# RN821X_RN721X_SOC_V2 register map
File version: v1.0.7
CPU: CM0 r0p0, little endian, no MPU, no FPU, 3 interrupt priority bits
Registers are 32-bit, read-write, reset 0x0 unless marked. A register's access mark holds for its fields unless they carry their own. Offsets are from the block's base; [hi:lo] are bit positions; {n}, {i} and the like mark numbered series.

## IOCNT — emu pulse forwarding module
Base 0x4006C000
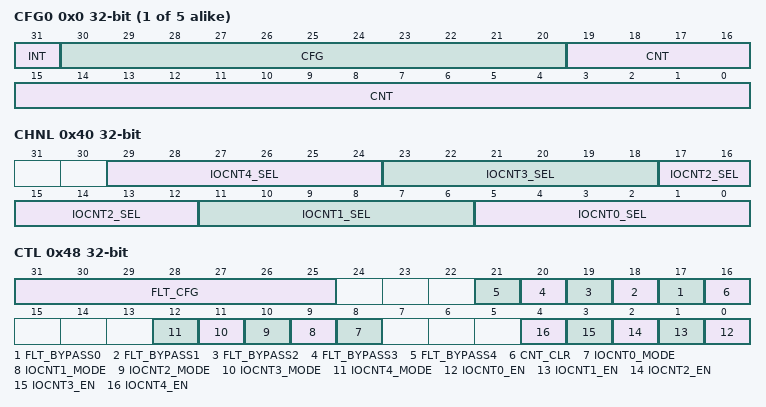
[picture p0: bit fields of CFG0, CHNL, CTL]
{0x0+4i} CFG{i} (i=0..4) — pulse forwarding configuration register{i+1}
  [31] INT — pluse inversion output enable bit
    0=NORM (output pulse level direction same as input pulse level); 1=INT (output pulse after it being inverted)
  [30:20] CFG — pluse freqency division configuration bits
  [19:0] CNT ro — pluse counter bits
{0x20+4i} OUT{i} (i=0..4) — pulse forwarding output counter register{i}
  [19:0] OUT{i} — pulse forwarding output counter bits
0x40 CHNL — pulse forwarding channel select register
  [6n+5:6n] IOCNT{n}_SEL (n=0..4) — IOCNT{n} input selection bits
0x48 CTL — pulse forwarding control register
  [31:25] FLT_CFG — IOCNT4~0 filter period config bits
  [n+17] FLT_BYPASS{n} (n=0..4) — IOCNT{n} FLT_BYPASS enable bit
  [16] CNT_CLR — pulse counter mode selection bit
  [n+8] IOCNT{n}_MODE (n=0..4) — IOCNT{n} count mode selection bit
  [n] IOCNT{n}_EN (n=0..4) — IOCNT{n} enable bit

## KBI — key detection
Base 0x40028000
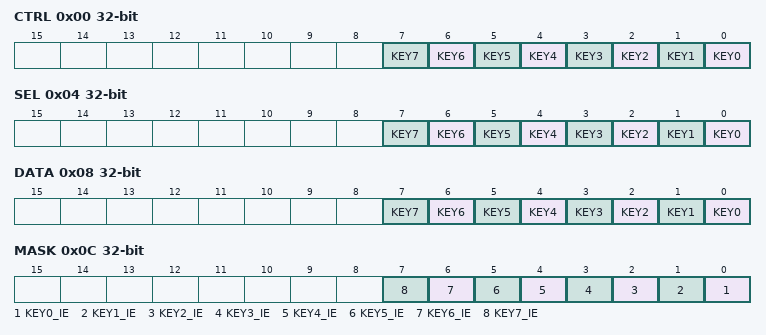
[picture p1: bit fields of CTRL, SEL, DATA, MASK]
0x00 CTRL — KBI control register
  [n] KEY{n} (n=0..7) — KBI KEY{n} enable/disable bit
    1=EN (KBI KEY{n} enable); 0=DIS (KBI KEY{n} disable)
0x04 SEL — KBI trigger mode select register
  [all] fields
    0=PE (KBI select posedge sampling); 1=NE (KBI select negedge sampling)
  [n] KEY{n} (n=0..7) — KBI KEY{n} posedge/negedge selection bit
0x08 DATA — KBI data register
  [all] fields
    1=PD (KEY pressed); 0=NUL (KEY not be pressed)
  [n] KEY{n} write-1-clears (n=0..7) — KBI KEY{n} data bit indicate key pressed or not
0x0C MASK — KBI interrupt mask register
  [n] KEY{n}_IE (n=0..7) — KBI KEY{n} interrupt enable/disable bit

## M2M — DMA memory access
Base 0x40068000
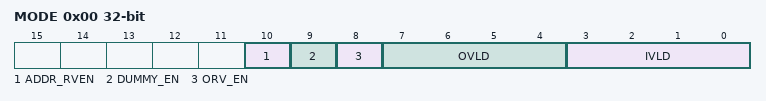
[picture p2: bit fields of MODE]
0x00 MODE — M2M mode register
  [10] ADDR_RVEN — address order reverse enable bit
  [9] DUMMY_EN — dummy byte enable bit
  [8] ORV_EN — byte order reverse enable bit
  [7:4] OVLD — output Data valid byte configuration bits
  [3:0] IVLD — input Data valid byte configuration bits
0x04 CTL — M2M control register
  [0] M2M_EN — M2M enable bit
0x08 DUMMY — M2M dummy register
  [31:0] DUMMY — M2M dummy register bits
0x0C SADDR — M2M source address register
  [16:0] SADDR — M2M source address register bits
0x10 DADDR — M2M destination address register
  [16:0] DADDR — M2M done interrupt enable bit
0x14 ILEN — M2M length register
  [16:0] ILEN — M2M input length configuration bits
0x18 IE — M2M interrupt enable register
  [0] IE — M2M interrupt enable bit
0x1C IF — M2M interrupt flag register
  [0] IF — M2M interrupt flag

## SIMP_TC0 — simple tc
Base 0x40060000
Same registers: SIMP_TC1 0x4006000C, SIMP_TC2 0x40060018, SIMP_TC3 0x40060024
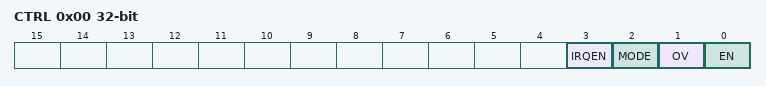
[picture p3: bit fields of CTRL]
0x00 CTRL — SIMP_TC control register
  [3] IRQEN — SIMP_TC interrupt enable bit
  [2] MODE — SIMP_TC count mode selection bit
    0=SINGLE (SIMP_TC select as single pulse mode); 1=REPETITIVE (SIMP_TC select as repetitive pulse mode)
  [1] OV write-1-clears — SIMP_TC overflow flag
  [0] EN — SIMP_TC enable bit
0x04 LOAD — SIMP_TC target counter register
  [31:0] LOAD — SIMP_TC target counting value setting bits
0x08 VAL — SIMP_TC counter register bits
  [31:0] VAL — SIMP_TC current count register bits

## WDT — watchdog timer
Base 0x40030000
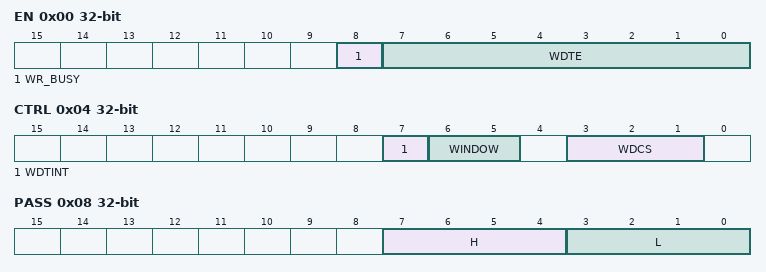
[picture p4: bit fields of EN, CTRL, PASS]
0x00 EN — Watchdog enable register
  [8] WR_BUSY ro — WDT write busy flag
  [7:0] WDTE — WDT enable bits
    187=RESTART (clear WDT counter and restart WDT(write value)); 85=DIS_DFLT (WDTE default value)
0x04 CTRL — WDT control register
  [7] WDTINT — WDT Timer Interval Interrupt
  [6:5] WINDOW — WDT Window Open Period
  [3:1] WDCS — WDT overflow time config
0x08 PASS — WDT password register
  [7:4] H ro — WDT high part password
  [3:0] L — WDT low part password
0x14 HALT — WDT HALT control register
  [15:0] EN — HALT_EN config bits
0x18 STBY — WDT STBY control register
  [15:0] EN — STBY_EN config bits
